# PIC32CX2051BZ62132 device description
Architecture: CORTEX-M4; Family: PIC32CX; Series: PIC32CXBZ62
Registers are 32-bit, read-write, reset 0x0 unless marked. A register's access mark holds for its fields unless they carry their own. Offsets are from the block's base; [hi:lo] are bit positions; {n}, {i} and the like mark numbered series.

## PAC — Peripheral Access Controller
Instances: PAC 0x40000000
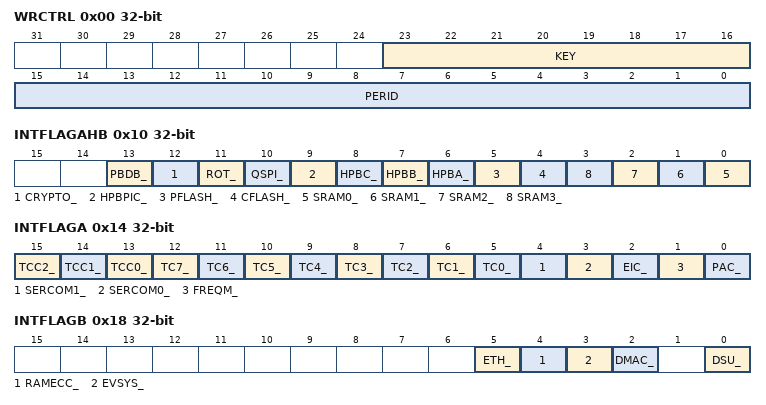
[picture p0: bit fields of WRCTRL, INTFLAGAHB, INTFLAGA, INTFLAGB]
0x00 WRCTRL — Write control
  [23:16] KEY — Peripheral access control key
    0=OFF (No action); 1=CLR (Clear protection); 2=SET (Set protection); 3=SETLCK (Set and lock protection)
  [15:0] PERID — Peripheral identifier
0x04 EVCTRL 8-bit — Event control
  [0] ERREO — Peripheral acess error event output
0x08 INTENCLR 8-bit (atomic clear) — Interrupt enable clear
  [0] ERR — Peripheral access error interrupt disable
0x09 INTENSET 8-bit (atomic set) — Interrupt enable set
  [0] ERR — Peripheral access error interrupt enable
0x10 INTFLAGAHB (atomic clear) — Bridge interrupt flag status
  [13] PBDB_
  [12] CRYPTO_
  [11] ROT_
  [10] QSPI_
  [9] HPBPIC_ — HPBPIC0
  [8] HPBC_
  [7] HPBB_
  [6] HPBA_
  [5] PFLASH_
  [4] CFLASH_
  [n] SRAM{n}_ (n=0..3)
0x14 INTFLAGA (atomic clear) — Peripheral interrupt flag status - Bridge A
  [15] TCC2_, [14] TCC1_, [13] TCC0_, [n+5] TC{n}_ (n=0..7), [4] SERCOM1_, [3] SERCOM0_, [2] EIC_, [1] FREQM_, [0] PAC_
0x18 INTFLAGB (atomic clear) — Peripheral interrupt flag status - Bridge B
  [5] ETH_, [4] RAMECC_, [3] EVSYS_, [2] DMAC_, [0] DSU_
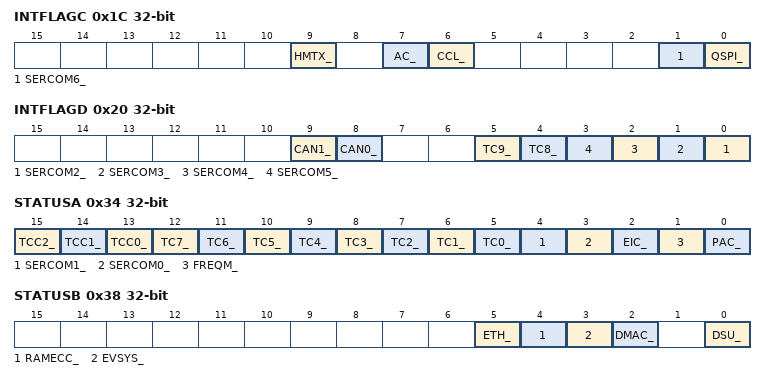
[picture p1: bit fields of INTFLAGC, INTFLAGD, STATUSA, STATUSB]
0x1C INTFLAGC (atomic clear) — Peripheral interrupt flag status - Bridge C
  [9] HMTX_, [7] AC_, [6] CCL_, [1] SERCOM6_, [0] QSPI_
0x20 INTFLAGD (atomic clear) — Peripheral interrupt flag status - Bridge D
  [9] CAN1_, [8] CAN0_, [5] TC9_, [4] TC8_, [n-2] SERCOM{n}_ (n=2..5)
0x34 STATUSA ro — Peripheral write protection status - Bridge A
  [15] TCC2_ — TCC2 APB Protect Enable
  [14] TCC1_ — TCC1 APB Protect Enable
  [13] TCC0_ — TCC0 APB Protect Enable
  [n+5] TC{n}_ (n=0..7) — TC{n} APB Protect Enable
  [4] SERCOM1_ — SERCOM1 APB Protect Enable
  [3] SERCOM0_ — SERCOM0 APB Protect Enable
  [2] EIC_ — EIC APB Protect Enable
  [1] FREQM_ — FREQM APB Protect Enable
  [0] PAC_ — PAC APB Protect Enable
0x38 STATUSB ro — Peripheral write protection status - Bridge B
  [5] ETH_ — ETH APB Protect Enable
  [4] RAMECC_ — RAMECC APB Protect Enable
  [3] EVSYS_ — EVSYS APB Protect Enable
  [2] DMAC_ — DMAC APB Protect Enable
  [0] DSU_ — DSU APB Protect Enable
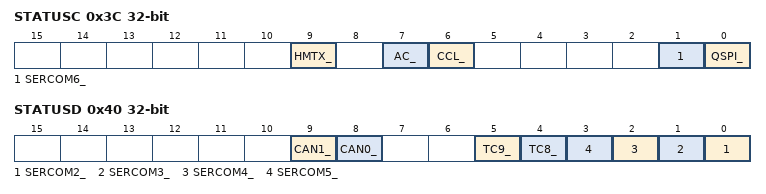
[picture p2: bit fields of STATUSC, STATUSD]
0x3C STATUSC ro — Peripheral write protection status - Bridge C
  [9] HMTX_ — HMTX Protect Enable
  [7] AC_ — AC APB Protect Enable
  [6] CCL_ — CCL APB Protect Enable
  [1] SERCOM6_ — SERCOM6 APB Protect Enable
  [0] QSPI_ — QSPI APB Protect Enable
0x40 STATUSD ro — Peripheral write protection status - Bridge D
  [9] CAN1_ — CAN1 APB Protect Enable
  [8] CAN0_ — CAN0 APB Protect Enable
  [5] TC9_ — TC9 APB Protect Enable
  [4] TC8_ — TC8 APB Protect Enable
  [n-2] SERCOM{n}_ (n=2..5) — SERCOM{n} APB Protect Enable

## PCHE — this is the PCHE
Instances: PCHE 0x44012400
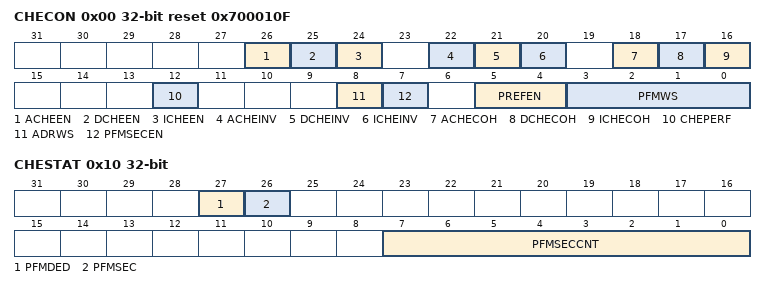
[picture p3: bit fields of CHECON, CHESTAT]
0x00 CHECON reset 0x700010F
  [26] ACHEEN, [25] DCHEEN, [24] ICHEEN, [22] ACHEINV, [21] DCHEINV, [20] ICHEINV, [18] ACHECOH, [17] DCHECOH, [16] ICHECOH, [12] CHEPERF, [8] ADRWS, [7] PFMSECEN, [5:4] PREFEN, [3:0] PFMWS
0x04 CHECONCLR
0x08 CHECONSET
0x0C CHECONINV
0x10 CHESTAT
  [27] PFMDED, [26] PFMSEC, [7:0] PFMSECCNT
0x14 CHESTATCLR
0x18 CHESTATSET
0x1C CHESTATINV
0x20 CHEHIT
0x24 CHEHITCLR
0x28 CHEHITSET
0x2C CHEHITINV
0x30 CHEMIS
0x34 CHEMISCLR
0x38 CHEMISSET
0x3C CHEMISINV

## PFW — flash wrapper
Instances: PFW 0x44000800
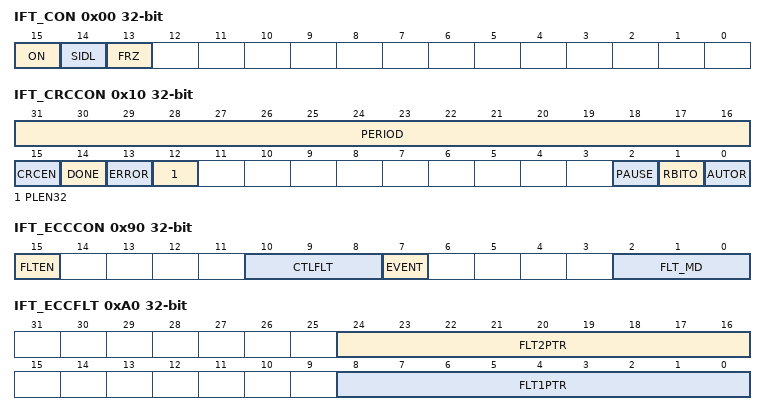
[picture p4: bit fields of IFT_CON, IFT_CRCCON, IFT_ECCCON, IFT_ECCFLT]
0x00 IFT_CON
  [15] ON, [14] SIDL, [13] FRZ
0x10 IFT_CRCCON
  [31:16] PERIOD, [15] CRCEN, [14] DONE, [13] ERROR, [12] PLEN32, [2] PAUSE, [1] RBITO, [0] AUTOR
0x20 IFT_CRCMADR
0x30 IFT_CRCMLEN
  [23:0] CRCMLEN
0x40 IFT_CRCIV
0x50 IFT_CRCACC
0x60 IFT_CRCPOLY
  [31:0] CYCPOLY
0x70 IFT_CRCFXOR
0x80 IFT_CRCSUM
0x90 IFT_ECCCON
  [15] FLTEN, [10:8] CTLFLT, [7] EVENT, [2:0] FLT_MD
0xA0 IFT_ECCFLT
  [24:16] FLT2PTR, [8:0] FLT1PTR
0xB0 IFT_ECCADR
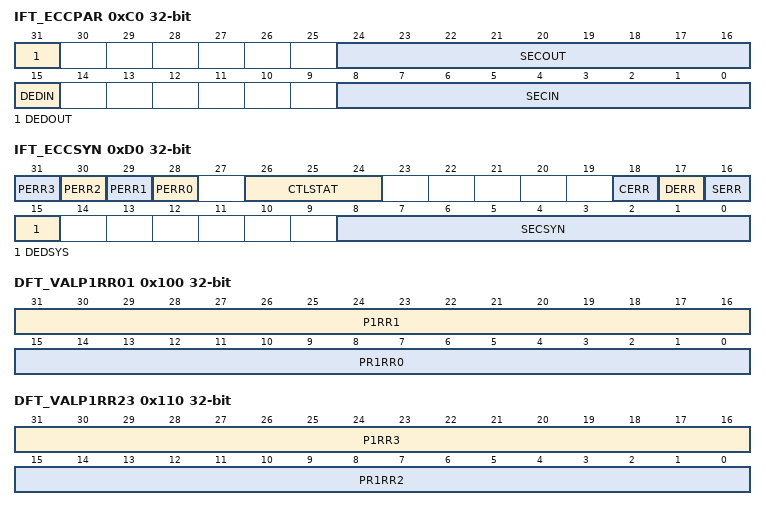
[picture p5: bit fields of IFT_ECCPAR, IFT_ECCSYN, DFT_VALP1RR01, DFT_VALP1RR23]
0xC0 IFT_ECCPAR
  [31] DEDOUT, [24:16] SECOUT, [15] DEDIN, [8:0] SECIN
0xD0 IFT_ECCSYN
  [n+28] PERR{n} (n=0..3), [26:24] CTLSTAT, [18] CERR, [17] DERR, [16] SERR, [15] DEDSYS, [8:0] SECSYN
0xF0 DFT_VALCON
  [15] VAL_ON
0x100 DFT_VALP1RR01
  [31:16] P1RR1, [15:0] PR1RR0
0x110 DFT_VALP1RR23
  [31:16] P1RR3, [15:0] PR1RR2
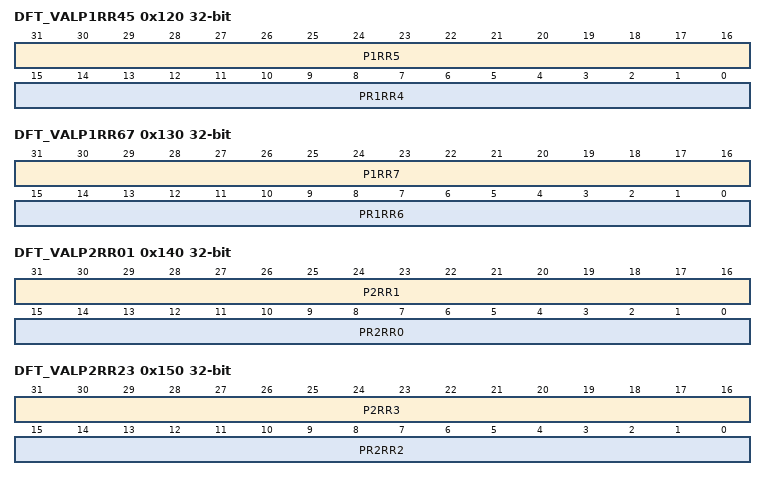
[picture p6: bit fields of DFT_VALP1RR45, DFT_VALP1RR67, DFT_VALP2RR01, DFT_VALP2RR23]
0x120 DFT_VALP1RR45
  [31:16] P1RR5, [15:0] PR1RR4
0x130 DFT_VALP1RR67
  [31:16] P1RR7, [15:0] PR1RR6
0x140 DFT_VALP2RR01
  [31:16] P2RR1, [15:0] PR2RR0
0x150 DFT_VALP2RR23
  [31:16] P2RR3, [15:0] PR2RR2
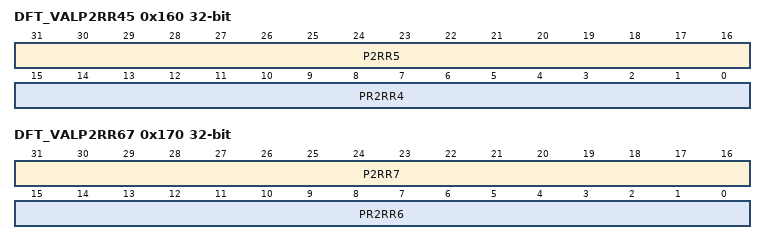
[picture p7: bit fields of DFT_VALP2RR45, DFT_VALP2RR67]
0x160 DFT_VALP2RR45
  [31:16] P2RR5, [15:0] PR2RR4
0x170 DFT_VALP2RR67
  [31:16] P2RR7, [15:0] PR2RR6
